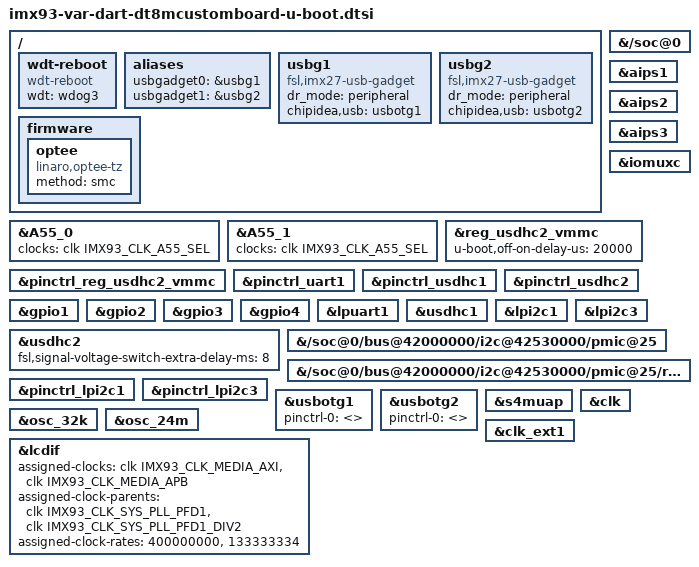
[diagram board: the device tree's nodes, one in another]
// SPDX-License-Identifier: GPL-2.0+
/*
 * Copyright 2022 NXP
 * Copyright 2023-2025 Variscite Ltd.
 */

/ {
	wdt-reboot {
		compatible = "wdt-reboot";
		wdt = <&wdog3>;
		bootph-pre-ram;
		bootph-some-ram;
	};

	aliases {
		usbgadget0 = &usbg1;
		usbgadget1 = &usbg2;
	};

	usbg1: usbg1 {
		compatible = "fsl,imx27-usb-gadget";
		dr_mode = "peripheral";
		chipidea,usb = <&usbotg1>;
		status = "okay";
	};

	usbg2: usbg2 {
		compatible = "fsl,imx27-usb-gadget";
		dr_mode = "peripheral";
		chipidea,usb = <&usbotg2>;
		status = "okay";
	};

	firmware {
		optee {
			compatible = "linaro,optee-tz";
			method = "smc";
		};
	};
};

&A55_0 {
	clocks = <&clk IMX93_CLK_A55_SEL>;
};

&A55_1 {
	clocks = <&clk IMX93_CLK_A55_SEL>;
};

&{/soc@0} {
	bootph-all;
	bootph-pre-ram;
};

&aips1 {
	bootph-pre-ram;
	bootph-all;
};

&aips2 {
	bootph-pre-ram;
	bootph-some-ram;
};

&aips3 {
	bootph-pre-ram;
	bootph-some-ram;
};

&iomuxc {
	bootph-pre-ram;
	bootph-some-ram;
};

&reg_usdhc2_vmmc {
	u-boot,off-on-delay-us = <20000>;
	bootph-pre-ram;
};

&pinctrl_reg_usdhc2_vmmc {
	bootph-pre-ram;
};

&pinctrl_uart1 {
	bootph-pre-ram;
	bootph-some-ram;
};

&pinctrl_usdhc1 {
	bootph-pre-ram;
};

&pinctrl_usdhc2 {
	bootph-pre-ram;
};

&gpio1 {
	bootph-pre-ram;
	bootph-some-ram;
};

&gpio2 {
	bootph-pre-ram;
	bootph-some-ram;
};

&gpio3 {
	bootph-pre-ram;
	bootph-some-ram;
};

&gpio4 {
	bootph-pre-ram;
	bootph-some-ram;
};

&lpuart1 {
	bootph-pre-ram;
	bootph-some-ram;
};

&usdhc1 {
	bootph-pre-ram;
};

&usdhc2 {
	bootph-pre-ram;
	fsl,signal-voltage-switch-extra-delay-ms = <8>;
};

&lpi2c1 {
	bootph-pre-ram;
	bootph-all;
};

&lpi2c3 {
	bootph-pre-ram;
};

&{/soc@0/bus@42000000/i2c@42530000/pmic@25} {
	bootph-pre-ram;
};

&{/soc@0/bus@42000000/i2c@42530000/pmic@25/regulators} {
	bootph-pre-ram;
};

&pinctrl_lpi2c1 {
	bootph-pre-ram;
	bootph-all;
};

&pinctrl_lpi2c3 {
	bootph-pre-ram;
};

&usbotg1 {
	pinctrl-names = "default";
	pinctrl-0 = <>;
};

&usbotg2 {
	pinctrl-names = "default";
	pinctrl-0 = <>;
};

&s4muap {
	bootph-pre-ram;
	bootph-some-ram;
	status = "okay";
};

&clk {
	bootph-all;
	bootph-pre-ram;
	/delete-property/ assigned-clocks;
	/delete-property/ assigned-clock-rates;
	/delete-property/ assigned-clock-parents;
};

&osc_32k {
	bootph-all;
	bootph-pre-ram;
};

&osc_24m {
	bootph-all;
	bootph-pre-ram;
};

&clk_ext1 {
	bootph-all;
	bootph-pre-ram;
};

&lcdif {
	assigned-clocks = <&clk IMX93_CLK_MEDIA_AXI>, <&clk IMX93_CLK_MEDIA_APB>;
	assigned-clock-parents = <&clk IMX93_CLK_SYS_PLL_PFD1>, <&clk IMX93_CLK_SYS_PLL_PFD1_DIV2>;
	assigned-clock-rates = <400000000>, <133333334>;
};
